# NUC100BN_v1 register map
File version: 1.0
Registers are 32-bit, read-write, reset 0x0 unless marked. A register's access mark holds for its fields unless they carry their own. Offsets are from the block's base; [hi:lo] are bit positions; 'fields as' and 'values as' point back to an identical list.

## TMR23 — TMR Register Map
Base 0x40110000
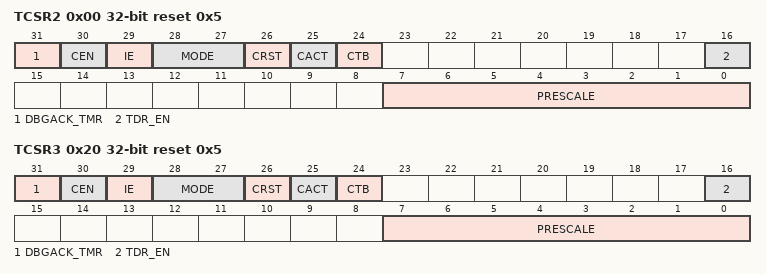
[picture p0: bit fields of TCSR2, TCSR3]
0x00 TCSR2 reset 0x5 — Timer2 Control and Status Register
  [31] DBGACK_TMR — ICE Debug Mode Acknowledge Disable (Write-protection Bit). TIMER counter will keep going no matter ICE debug mode acknowledged or not.
    0=ICE debug mode acknowledgement effects TIMER counting; 1=ICE debug mode acknowledgement disabled
  [30] CEN — Timer Enable Bit
    0=Stops/Suspends counting; 1=Starts counting
  [29] IE — Interrupt Enable Bit. If timer interrupt is enabled, the timer asserts its interrupt signal when the associated up-timer value is equal to TCMPR.
    0=Timer Interrupt Disabled; 1=Timer Interrupt Enabled
  [28:27] MODE — Timer Operating Mode
  [26] CRST — Timer Reset Bit. Setting this bit will reset the 24-bit up-timer, 8-bit pre-scale counter and also force CEN to 0.
    0=No effect; 1=Reset Timer's 8-bit pre-scale counter, internal 24-bit up-timer and CEN bit
  [25] CACT ro — Timer Active Status Bit (Read Only). This bit indicates the up-timer status.
    0=Timer is not active; 1=Timer is active
  [24] CTB — Counter Mode Enable Bit (NuMicro( NUC100/NUC120 Low Density Only). This bit is the counter mode enable bit. When Timer is used as an event counter, this bit should be set to 1 and Timer will work as an event counter. The event is triggered by rising edge from external pin
    0=Disabled counter mode; 1=counter mode Enabled
  [16] TDR_EN — Data Load Enable. When TDR_EN is set, TDR (Timer Data Register) will be updated continuously with the 24-bit up-timer value as the timer is counting.
    0=Timer Data Register update Disabled; 1=Timer Data Register update Enabled
  [7:0] PRESCALE — Pre-scale Counter
0x04 TCMPR2 — Timer2 Compare Register
  [23:0] TCMP — Timer Compared Value. Note1: Never write 0x0 or 0x1 in TCMP, or the core will run into unknown state. Note2: When timer is operating at continuous counting mode, the 24-bit up-timer will count continuously if software writes a new value into TCMP. If timer is operating at other modes, the 24-bit up-timer will restart counting and using newest TCMP value to be the compared value if software writes a new value into TCMP.
0x08 TISR2 — Timer2 Interrupt Status Register
  [0] TIF — Timer Interrupt Flag. This bit indicates the interrupt status of Timer. TIF bit is set by hardware when the up counting value of internal 24-bit up-timer matches the timer compared value (TCMP). It is cleared by writing 1 to this bit.
0x0C TDR2 ro — Timer2 Data Register
  [23:0] TDR — Timer Data Register. When TCSR.TDR_EN is set to 1, the internal 24-bit up-timer value will be loaded into TDR. User can read this register for the up-timer value.
0x20 TCSR3 reset 0x5 — Timer3 Control and Status Register
  fields as TCSR2
0x24 TCMPR3 — Timer3 Compare Register
  fields as TCMPR2
0x28 TISR3 — Timer3 Interrupt Status Register
  fields as TISR2
0x2C TDR3 ro — Timer3 Data Register
  fields as TDR2

## WDT — WDT Register Map
Base 0x40004000
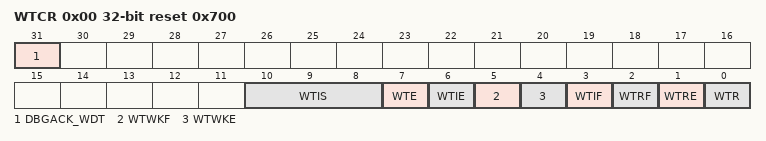
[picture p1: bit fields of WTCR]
0x00 WTCR reset 0x700 — Watchdog Timer Control Register
  [31] DBGACK_WDT — ICE Debug Mode Acknowledge Disable (Write-protection Bit). Watchdog Timer counter will keep going no matter ICE debug mode acknowledged or not.
    0=ICE debug mode acknowledgement affects Watchdog Timer counting; 1=ICE debug mode acknowledgement disabled
  [10:8] WTIS — Watchdog Timer Interval Selection (Write-protection Bits)
  [7] WTE — Watchdog Timer Enable (Write-protection Bit)
    0=Watchdog timer Disabled (This action will reset the internal counter); 1=Watchdog timer Enabled
  [6] WTIE — Watchdog Timer Interrupt Enable (Write-protection Bit)
    0=Watchdog timer interrupt Disabled; 1=Watchdog timer interrupt Enabled
  [5] WTWKF — Watchdog Timer Wake-up Flag. If Watchdog timer causes chip wakes up from Power-down mode, this bit will be set to high. It must be cleared by software with a write 1 to this bit.
    0=Watchdog timer does not cause chip wake-up; 1=Chip wake-up from Idle or Power-down mode by Watchdog timeout
  [4] WTWKE — Watchdog Timer Wake-up Function Enable bit (Write-protection Bit). Note: Chip can be woken up by WDT only if WDT clock source selects RC10K.
    0=Watchdog timer Wake-up chip function Disabled; 1=Wake-up function Enabled so that Watchdog timer timeout can wake-up chip from Power-down mode
  [3] WTIF — Watchdog Timer Interrupt Flag. If the Watchdog timer interrupt is enabled, this bit will be set to indicate that Watchdog timer interrupt has occurred. Note: This bit is cleared by writing 1 to this bit.
    0=Watchdog timer interrupt did not occur; 1=Watchdog timer interrupt occurred
  [2] WTRF — Watchdog Timer Reset Flag. When the Watchdog timer initiates a reset, the hardware will set this bit. This flag can be read by software to determine the source of reset. Software is responsible to clear it manually by writing 1 to it. If WTRE is disabled, then the Watchdog timer has no effect on this bit. Note: This bit is cleared by writing 1 to this bit.
    0=Watchdog timer reset did not occur; 1=Watchdog timer reset occurred
  [1] WTRE — Watchdog Timer Reset Enable (Write-protection Bit). Setting this bit will enable the Watchdog timer reset function.
    0=Watchdog timer reset function Disabled; 1=Watchdog timer reset function Enabled
  [0] WTR — Clear Watchdog Timer (Write-protection Bit). Set this bit will clear the Watchdog timer. Note: This bit will be automatically cleared by hardware.
    0=No effect; 1=Reset the contents of the Watchdog timer
